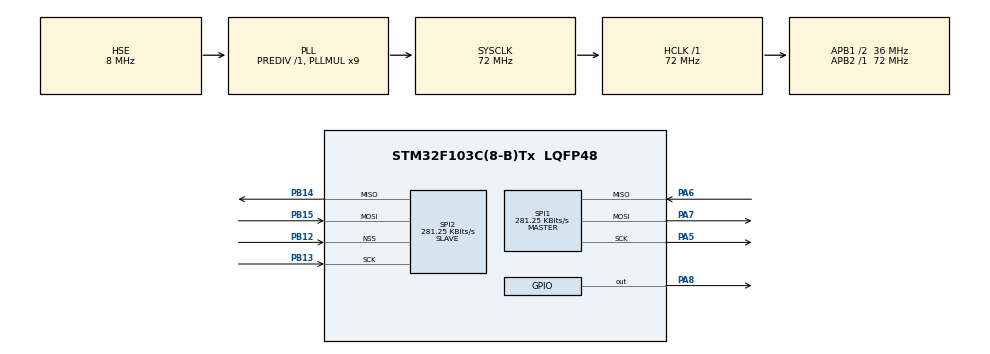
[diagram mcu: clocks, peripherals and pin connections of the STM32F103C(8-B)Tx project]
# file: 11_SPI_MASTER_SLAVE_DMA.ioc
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Mcu.Family=STM32F1
RCC.PLLSourceVirtual=RCC_PLLSOURCE_HSE
Dma.SPI2_RX.0.Instance=DMA1_Channel4
PA6.Mode=Full_Duplex_Master
SPI2.VirtualNSS=VM_NSSHARD
Dma.SPI1_RX.1.Mode=DMA_CIRCULAR
PA7.Mode=Full_Duplex_Master
PD1-OSC_OUT.Mode=HSE-External-Oscillator
SPI1.VirtualType=VM_MASTER
SPI2.VirtualType=VM_SLAVE
Dma.SPI2_RX.0.Mode=DMA_CIRCULAR
Dma.SPI1_RX.1.MemDataAlignment=DMA_MDATAALIGN_BYTE
PD0-OSC_IN.Signal=RCC_OSC_IN
RCC.APB1CLKDivider=RCC_HCLK_DIV2
PB15.Signal=SPI2_MOSI
PB13.Signal=SPI2_SCK
RCC.SYSCLKSource=RCC_SYSCLKSOURCE_PLLCLK
ProjectManager.StackSize=0x800
PD1-OSC_OUT.Signal=RCC_OSC_OUT
PA13.Signal=SYS_JTMS-SWDIO
Dma.SPI2_RX.0.PeriphDataAlignment=DMA_PDATAALIGN_BYTE
NVIC.DMA1_Channel2_IRQn=true\:0\:0\:false\:false\:true\:false\:true
ProjectManager.TargetToolchain=STM32CubeIDE
Dma.SPI1_RX.1.PeriphInc=DMA_PINC_DISABLE
SPI1.Direction=SPI_DIRECTION_2LINES
RCC.HCLKFreq_Value=72000000
RCC.APB2TimFreq_Value=72000000
SPI1.CalculateBaudRate=281.25 KBits/s
RCC.USBFreq_Value=72000000
RCC.AHBFreq_Value=72000000
SPI2.BaudRatePrescaler=SPI_BAUDRATEPRESCALER_128
PD0-OSC_IN.Mode=HSE-External-Oscillator
PB14.Signal=SPI2_MISO
PA5.Signal=SPI1_SCK
Dma.SPI1_RX.1.Priority=DMA_PRIORITY_LOW
board=custom
RCC.PLLMUL=RCC_PLL_MUL9
PB15.Mode=Full_Duplex_Slave
NVIC.SPI1_IRQn=true\:0\:0\:false\:false\:true\:true\:true
RCC.APB2Freq_Value=72000000
SPI1.Mode=SPI_MODE_MASTER
PA14.Mode=Serial_Wire
PB14.Mode=Full_Duplex_Slave
SPI2.CalculateBaudRate=281.25 KBits/s
Dma.SPI2_RX.0.MemDataAlignment=DMA_MDATAALIGN_BYTE
PA8.Signal=GPIO_Output
NVIC.SPI2_IRQn=true\:0\:0\:false\:false\:true\:true\:true
PA13.Mode=Serial_Wire
Dma.SPI2_RX.0.Priority=DMA_PRIORITY_LOW
Mcu.Name=STM32F103C(8-B)Tx
Dma.SPI1_RX.1.Direction=DMA_PERIPH_TO_MEMORY
Dma.SPI2_RX.0.MemInc=DMA_MINC_ENABLE
Dma.SPI1_RX.1.PeriphDataAlignment=DMA_PDATAALIGN_BYTE
RCC.SYSCLKFreq_VALUE=72000000
Mcu.Package=LQFP48
PA6.Signal=SPI1_MISO
PB12.Mode=NSS_Signal_Hard_Input
SPI2.Mode=SPI_MODE_SLAVE
Dma.SPI2_RX.0.PeriphInc=DMA_PINC_DISABLE
PA14.Signal=SYS_JTCK-SWCLK
ProjectManager.HeapSize=0x400
NVIC.PriorityGroup=NVIC_PRIORITYGROUP_4
Dma.Request1=SPI1_RX
RCC.APB1TimFreq_Value=72000000
SPI2.Direction=SPI_DIRECTION_2LINES
Dma.SPI2_RX.0.Direction=DMA_PERIPH_TO_MEMORY
PB13.Mode=Full_Duplex_Slave
NVIC.DMA1_Channel4_IRQn=true\:0\:0\:false\:false\:true\:false\:true
Dma.Request0=SPI2_RX
RCC.APB1Freq_Value=36000000
SPI1.BaudRatePrescaler=SPI_BAUDRATEPRESCALER_256
Dma.SPI1_RX.1.MemInc=DMA_MINC_ENABLE
PA8.GPIO_Speed=GPIO_SPEED_FREQ_HIGH
PB12.Signal=SPI2_NSS
PA8.PinState=GPIO_PIN_SET
PA5.Mode=Full_Duplex_Master
PA7.Signal=SPI1_MOSI
Dma.SPI1_RX.1.Instance=DMA1_Channel2

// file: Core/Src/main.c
/* USER CODE BEGIN Header */
/**
 ******************************************************************************
 * @file           : main.c
 * @brief          : Main program body
 ******************************************************************************
 * @attention
 *
 * <h2><center>&copy; Copyright (c) 2021 STMicroelectronics.
 * All rights reserved.</center></h2>
 *
 * This software component is licensed by ST under BSD 3-Clause license,
 * the "License"; You may not use this file except in compliance with the
 * License. You may obtain a copy of the License at:
 *                        opensource.org/licenses/BSD-3-Clause
 *
 ******************************************************************************
 */
/* USER CODE END Header */
#include "main.h"

/* USER CODE BEGIN Includes */
#define SPI2_ENABLE 	HAL_GPIO_WritePin(GPIOA, GPIO_PIN_8, GPIO_PIN_RESET);
#define SPI2_DISABLE 	HAL_GPIO_WritePin(GPIOA, GPIO_PIN_8, GPIO_PIN_SET);
/* USER CODE END Includes */

SPI_HandleTypeDef hspi1;
SPI_HandleTypeDef hspi2;
DMA_HandleTypeDef hdma_spi1_rx;
DMA_HandleTypeDef hdma_spi2_rx;

/* USER CODE BEGIN PV */
 uint16_t RX1, RX2, TX_Data=0;
/* USER CODE END PV */

void SystemClock_Config(void);
static void MX_GPIO_Init(void);
static void MX_DMA_Init(void);
static void MX_SPI1_Init(void);
static void MX_SPI2_Init(void);
/* USER CODE BEGIN PFP */
//void HAL_SPI_RxCpltCallback(SPI_HandleTypeDef* hspi)
//{
//
//}

void HAL_SPI_TxCpltCallback(SPI_HandleTypeDef* hspi)
{
	if(hspi -> Instance == hspi1.Instance)
	{
		SPI2_DISABLE;
	}
}
/* USER CODE END PFP */

int main(void)
{

  /* MCU Configuration--------------------------------------------------------*/

  /* Reset of all peripherals, Initializes the Flash interface and the Systick. */
  HAL_Init();

  /* Configure the system clock */
  SystemClock_Config();

  /* Initialize all configured peripherals */
  MX_GPIO_Init();
  MX_DMA_Init();
  MX_SPI1_Init();
  MX_SPI2_Init();
  /* USER CODE BEGIN 2 */
	HAL_SPI_Receive_DMA(&hspi1, &RX1, 1);
	HAL_SPI_Receive_DMA(&hspi2, &RX2, 1);
  /* USER CODE END 2 */

  /* Infinite loop */
	while (1) {

    /* USER CODE BEGIN 3 */
		SPI2_ENABLE;
		HAL_SPI_Transmit_IT(&hspi1, &TX_Data, 1);
		TX_Data++;
		HAL_Delay(1000);

	}
  /* USER CODE END 3 */
}

void SystemClock_Config(void)
{
  RCC_OscInitTypeDef RCC_OscInitStruct = {0};
  RCC_ClkInitTypeDef RCC_ClkInitStruct = {0};

  /** Initializes the RCC Oscillators according to the specified parameters
  * in the RCC_OscInitTypeDef structure.
  */
  RCC_OscInitStruct.OscillatorType = RCC_OSCILLATORTYPE_HSE;
  RCC_OscInitStruct.HSEState = RCC_HSE_ON;
  RCC_OscInitStruct.HSEPredivValue = RCC_HSE_PREDIV_DIV1;
  RCC_OscInitStruct.HSIState = RCC_HSI_ON;
  RCC_OscInitStruct.PLL.PLLState = RCC_PLL_ON;
  RCC_OscInitStruct.PLL.PLLSource = RCC_PLLSOURCE_HSE;
  RCC_OscInitStruct.PLL.PLLMUL = RCC_PLL_MUL9;
  if (HAL_RCC_OscConfig(&RCC_OscInitStruct) != HAL_OK)
  {
    Error_Handler();
  }
  /** Initializes the CPU, AHB and APB buses clocks
  */
  RCC_ClkInitStruct.ClockType = RCC_CLOCKTYPE_HCLK|RCC_CLOCKTYPE_SYSCLK
                              |RCC_CLOCKTYPE_PCLK1|RCC_CLOCKTYPE_PCLK2;
  RCC_ClkInitStruct.SYSCLKSource = RCC_SYSCLKSOURCE_PLLCLK;
  RCC_ClkInitStruct.AHBCLKDivider = RCC_SYSCLK_DIV1;
  RCC_ClkInitStruct.APB1CLKDivider = RCC_HCLK_DIV2;
  RCC_ClkInitStruct.APB2CLKDivider = RCC_HCLK_DIV1;

  if (HAL_RCC_ClockConfig(&RCC_ClkInitStruct, FLASH_LATENCY_2) != HAL_OK)
  {
    Error_Handler();
  }
}

static void MX_SPI1_Init(void)
{

  /* SPI1 parameter configuration*/
  hspi1.Instance = SPI1;
  hspi1.Init.Mode = SPI_MODE_MASTER;
  hspi1.Init.Direction = SPI_DIRECTION_2LINES;
  hspi1.Init.DataSize = SPI_DATASIZE_8BIT;
  hspi1.Init.CLKPolarity = SPI_POLARITY_LOW;
  hspi1.Init.CLKPhase = SPI_PHASE_1EDGE;
  hspi1.Init.NSS = SPI_NSS_SOFT;
  hspi1.Init.BaudRatePrescaler = SPI_BAUDRATEPRESCALER_256;
  hspi1.Init.FirstBit = SPI_FIRSTBIT_MSB;
  hspi1.Init.TIMode = SPI_TIMODE_DISABLE;
  hspi1.Init.CRCCalculation = SPI_CRCCALCULATION_DISABLE;
  hspi1.Init.CRCPolynomial = 10;
  if (HAL_SPI_Init(&hspi1) != HAL_OK)
  {
    Error_Handler();
  }

}

static void MX_SPI2_Init(void)
{

  /* SPI2 parameter configuration*/
  hspi2.Instance = SPI2;
  hspi2.Init.Mode = SPI_MODE_SLAVE;
  hspi2.Init.Direction = SPI_DIRECTION_2LINES;
  hspi2.Init.DataSize = SPI_DATASIZE_8BIT;
  hspi2.Init.CLKPolarity = SPI_POLARITY_LOW;
  hspi2.Init.CLKPhase = SPI_PHASE_1EDGE;
  hspi2.Init.NSS = SPI_NSS_HARD_INPUT;
  hspi2.Init.BaudRatePrescaler = SPI_BAUDRATEPRESCALER_128;
  hspi2.Init.FirstBit = SPI_FIRSTBIT_MSB;
  hspi2.Init.TIMode = SPI_TIMODE_DISABLE;
  hspi2.Init.CRCCalculation = SPI_CRCCALCULATION_DISABLE;
  hspi2.Init.CRCPolynomial = 10;
  if (HAL_SPI_Init(&hspi2) != HAL_OK)
  {
    Error_Handler();
  }

}

static void MX_DMA_Init(void)
{

  /* DMA controller clock enable */
  __HAL_RCC_DMA1_CLK_ENABLE();

  /* DMA interrupt init */
  /* DMA1_Channel2_IRQn interrupt configuration */
  HAL_NVIC_SetPriority(DMA1_Channel2_IRQn, 0, 0);
  HAL_NVIC_EnableIRQ(DMA1_Channel2_IRQn);
  /* DMA1_Channel4_IRQn interrupt configuration */
  HAL_NVIC_SetPriority(DMA1_Channel4_IRQn, 0, 0);
  HAL_NVIC_EnableIRQ(DMA1_Channel4_IRQn);

}

static void MX_GPIO_Init(void)
{
  GPIO_InitTypeDef GPIO_InitStruct = {0};

  /* GPIO Ports Clock Enable */
  __HAL_RCC_GPIOD_CLK_ENABLE();
  __HAL_RCC_GPIOA_CLK_ENABLE();
  __HAL_RCC_GPIOB_CLK_ENABLE();

  /*Configure GPIO pin Output Level */
  HAL_GPIO_WritePin(GPIOA, GPIO_PIN_8, GPIO_PIN_SET);

  /*Configure GPIO pin : PA8 */
  GPIO_InitStruct.Pin = GPIO_PIN_8;
  GPIO_InitStruct.Mode = GPIO_MODE_OUTPUT_PP;
  GPIO_InitStruct.Pull = GPIO_NOPULL;
  GPIO_InitStruct.Speed = GPIO_SPEED_FREQ_HIGH;
  HAL_GPIO_Init(GPIOA, &GPIO_InitStruct);

}

void Error_Handler(void)
{
	__disable_irq();
	while (1) {
	}
}

/************************ (C) COPYRIGHT STMicroelectronics *****END OF FILE****/
